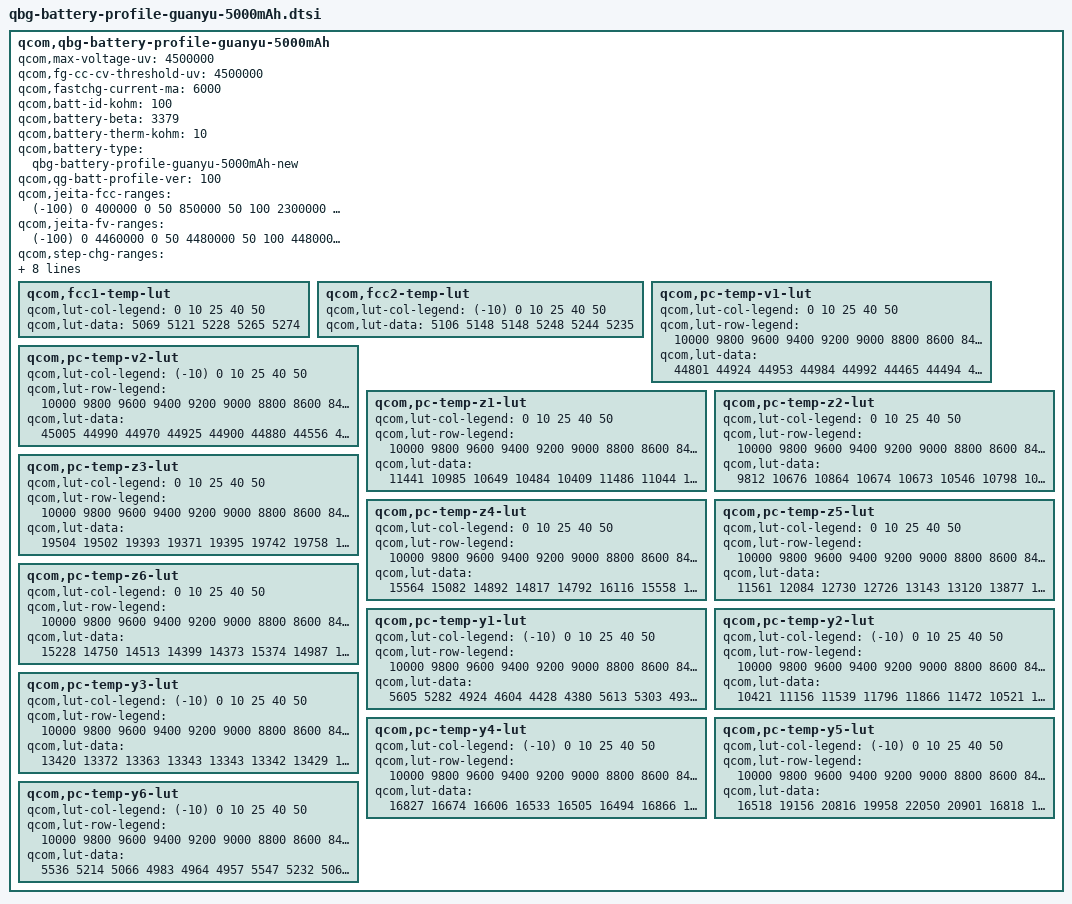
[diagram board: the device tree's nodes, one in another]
qcom,qbg-battery-profile-guanyu-5000mAh {
	qcom,max-voltage-uv = <4500000>;
	qcom,fg-cc-cv-threshold-uv = <4500000>;
	qcom,fastchg-current-ma = <6000>;
	qcom,batt-id-kohm = <100>;
	qcom,battery-beta = <3379>;
	qcom,battery-therm-kohm = <10>;
	qcom,battery-type = "qbg-battery-profile-guanyu-5000mAh-new";
	qcom,qg-batt-profile-ver = <100>;
	qcom,jeita-fcc-ranges = <(-100) 0 400000 0 50 850000 50 100 2300000 100 150 3700000 150 350 6000000 350 480 6000000 480 560 2300000 560 1500 0>;
	qcom,jeita-fv-ranges = <(-100) 0 4460000 0 50 4480000 50 100 4480000 100 150 4480000 150 350 4450000 350 480 4450000 480 560 4100000 560 1500 4100000>;
	qcom,step-chg-ranges = <3600000 4250000 6000000 4250001 4480000 5400000 4480001 4500000 3920000>;
	qcom,vbat-avg-based-step-chg;
	qcom,taper-fcc;
	qcom,jeita-soft-thresholds = <9556 3725>;
	qcom,jeita-hard-thresholds = <17365 2967>;
	qcom,jeita-soft-hys-thresholds = <8799 4060>;
	qcom,jeita-soft-fcc-ua = <5400000 2500000>;
	qcom,jeita-soft-fv-uv = <4480000 4100000>;

	qcom,fcc1-temp-lut {
		qcom,lut-col-legend = <0 10 25 40 50>;
		qcom,lut-data = <5069 5121 5228 5265 5274>;
	};

	qcom,fcc2-temp-lut {
		qcom,lut-col-legend = <(-10) 0 10 25 40 50>;
		qcom,lut-data = <5106 5148 5148 5248 5244 5235>;
	};

	qcom,pc-temp-v1-lut {
		qcom,lut-col-legend = <0 10 25 40 50>;
		qcom,lut-row-legend = <10000 9800 9600 9400 9200 9000 8800 8600 8400 8200 8000 7800 7600 7400 7200 7000 6800 6600 6400 6200 6000 5800 5600 5400 5200 5000 4800 4600 4400 4200 4000 3800 3600 3400 3200 3000 2800 2600 2400 2200 2000 1800 1600 1400 1200 1000 900 800 700 600 500 400 300 200 100 0>;
		qcom,lut-data = <44801 44924 44953 44984 44992
		                44465 44494 44525 44545 44562
		                44212 44226 44228 44219 44227
		                43947 43978 43957 43938 43939
		                43652 43692 43691 43677 43676
		                43363 43400 43403 43393 43396
		                43077 43112 43117 43113 43120
		                42793 42824 42832 42834 42844
		                42505 42546 42565 42575 42586
		                42227 42288 42315 42320 42328
		                41983 42047 42063 42065 42074
		                41745 41812 41820 41816 41824
		                41493 41572 41571 41561 41573
		                41172 41308 41318 41301 41310
		                40762 40996 41056 41045 41045
		                40307 40618 40760 40772 40760
		                39847 40204 40400 40427 40436
		                39442 39795 40007 40038 40047
		                39037 39371 39582 39612 39616
		                38599 38924 39140 39170 39166
		                38126 38423 38640 38692 38694
		                37618 37881 38106 38176 38187
		                37083 37314 37551 37621 37639
		                36544 36755 36990 37044 37052
		                35975 36195 36424 36466 36456
		                35372 35613 35840 35878 35868
		                34739 34996 35225 35262 35254
		                34123 34375 34605 34644 34638
		                33538 33770 33991 34030 34026
		                33042 33271 33458 33481 33482
		                32609 32868 33048 33062 33065
		                32252 32454 32579 32580 32582
		                31911 32110 32182 32182 32182
		                31578 31741 31792 31796 31798
		                31158 31331 31397 31402 31403
		                30626 30853 30971 30976 30978
		                30042 30372 30514 30516 30517
		                29470 29822 29965 29971 29971
		                28938 29277 29418 29425 29426
		                28402 28743 28878 28884 28885
		                27772 28138 28276 28282 28283
		                27050 27492 27633 27639 27640
		                26289 26750 26923 26942 26948
		                25514 26039 26264 26286 26291
		                24678 25358 25644 25665 25669
		                23722 24669 25048 25069 25072
		                22689 24028 24531 24558 24561
		                21698 23455 24076 24113 24115
		                22492 22896 23713 23753 23754
		                22641 22459 23388 23410 23411
		                22692 22402 23115 23095 23095
		                22935 22415 22514 22562 22562
		                22862 22414 22289 22293 22293
		                22036 22236 22245 22277 22277
		                21800 22213 22238 22254 22254
		                18745 19099 19099 19099 19099
		                19111 19111 19111 19111 19111>;
	};

	qcom,pc-temp-v2-lut {
		qcom,lut-col-legend = <(-10) 0 10 25 40 50>;
		qcom,lut-row-legend = <10000 9800 9600 9400 9200 9000 8800 8600 8400 8200 8000 7800 7600 7400 7200 7000 6800 6600 6400 6200 6000 5800 5600 5400 5200 5000 4800 4600 4400 4200 4000 3800 3600 3400 3200 3000 2800 2600 2400 2200 2000 1800 1600 1400 1200 1000 900 800 700 600 500 400 300 200 100 0>;
		qcom,lut-data = <45005 44990 44970 44925 44900 44880
		                44556 44590 44590 44564 44521 44498
		                44197 44272 44291 44294 44216 44183
		                43906 43989 44014 44026 43931 43895
		                43655 43753 43778 43782 43685 43648
		                43442 43549 43573 43556 43466 43431
		                43246 43368 43390 43346 43263 43230
		                43078 43199 43219 43165 43094 43066
		                42931 43041 43057 43002 42936 42910
		                42784 42881 42892 42838 42775 42752
		                42641 42731 42739 42683 42623 42602
		                42496 42582 42587 42527 42473 42454
		                42353 42432 42435 42368 42320 42305
		                42209 42272 42274 42199 42157 42146
		                42066 42106 42108 42022 41984 41977
		                41922 41936 41936 41838 41804 41801
		                41773 41762 41759 41662 41632 41628
		                41595 41559 41544 41436 41403 41398
		                41382 41328 41279 41166 41129 41123
		                41175 41140 41100 40997 40968 40970
		                41016 40997 40968 40877 40858 40869
		                40869 40856 40837 40783 40781 40788
		                40782 40770 40755 40708 40724 40720
		                40715 40703 40692 40634 40676 40659
		                40635 40624 40616 40542 40620 40601
		                40531 40517 40513 40426 40512 40508
		                40466 40462 40462 40316 40371 40383
		                40397 40403 40401 40220 40225 40245
		                40316 40334 40334 40131 40097 40108
		                40206 40238 40242 40014 40004 39984
		                40037 40079 40092 39748 39839 39886
		                39880 39913 39930 39516 39711 39779
		                39765 39768 39767 39379 39567 39608
		                39588 39571 39537 39257 39388 39391
		                39347 39313 39264 39122 39193 39148
		                39087 39056 39006 38946 38958 38874
		                38793 38766 38718 38730 38705 38582
		                38497 38477 38432 38488 38454 38332
		                38260 38243 38202 38229 38199 38134
		                38092 38079 38045 37968 37940 37983
		                38037 38030 37993 37726 37695 37838
		                37949 37959 37936 37490 37452 37659
		                37832 37857 37844 37301 37210 37432
		                37627 37683 37678 37087 36961 37155
		                37344 37430 37428 36842 36739 36870
		                37045 37136 37139 36602 36542 36630
		                36782 36850 36844 36385 36370 36425
		                36558 36604 36585 36184 36204 36229
		                36354 36385 36348 35975 36034 36036
		                36160 36182 36129 35743 35845 35849
		                35973 35997 35940 35459 35601 35664
		                35804 35837 35781 35091 35251 35404
		                35583 35613 35550 34715 34851 35066
		                35289 35313 35243 34349 34430 34649
		                34888 34918 34842 33955 34014 34199
		                34473 34503 34422 33519 33594 33710
		                33980 34007 33924 32965 33023 33127
		                33310 33358 33265 32385 32478 32582
		                32712 32741 32634 31851 31944 32098
		                32231 32240 32155 31056 31165 31312
		                31492 31501 31459 30299 30375 30582
		                30813 30893 30848 29662 29765 30027
		                30258 30261 30191 28946 29168 29412
		                29678 29656 29588 27684 28255 28473
		                28689 28678 28651 26978 27460 27963
		                28197 28202 28145 25704 26798 27040
		                27269 27269 27123 24715 25933 26435
		                26815 26863 26836 23595 25435 25011
		                25875 26055 25936 21852 23826 24452
		                24665 24680 24725 19287 21648 22120
		                22503 22675 22720 16972 19442 19565
		                19794 20086 20287 15010 17588 17772
		                17871 17560 17772 12738 12192 12322
		                12468 11898 11879 12817 12100 12221
		                10423 12028 9322 12632 12051 9243
		                8693 10569 9210 12632 12051 9243>;
	};

	qcom,pc-temp-z1-lut {
		qcom,lut-col-legend = <0 10 25 40 50>;
		qcom,lut-row-legend = <10000 9800 9600 9400 9200 9000 8800 8600 8400 8200 8000 7800 7600 7400 7200 7000 6800 6600 6400 6200 6000 5800 5600 5400 5200 5000 4800 4600 4400 4200 4000 3800 3600 3400 3200 3000 2800 2600 2400 2200 2000 1800 1600 1400 1200 1000 900 800 700 600 500 400 300 200 100 0>;
		qcom,lut-data = <11441 10985 10649 10484 10409
		                11486 11044 10708 10566 10479
		                11487 11042 10711 10568 10480
		                11488 11052 10706 10560 10475
		                11497 11059 10707 10558 10475
		                11516 11063 10707 10558 10475
		                11520 11066 10704 10558 10475
		                11501 11064 10700 10558 10476
		                11469 11056 10695 10557 10476
		                11457 11049 10691 10554 10477
		                11451 11042 10691 10553 10477
		                11446 11037 10691 10553 10477
		                11442 11034 10692 10554 10478
		                11440 11032 10692 10554 10478
		                11450 11032 10692 10555 10481
		                11469 11034 10694 10557 10483
		                11470 11035 10699 10559 10485
		                11458 11033 10704 10562 10487
		                11451 11031 10710 10564 10489
		                11452 11033 10713 10567 10492
		                11456 11042 10713 10570 10495
		                11460 11049 10713 10573 10499
		                11465 11055 10713 10575 10500
		                11467 11059 10716 10576 10500
		                11463 11059 10719 10577 10501
		                11457 11058 10724 10580 10502
		                11461 11058 10728 10585 10505
		                11477 11064 10731 10588 10508
		                11484 11068 10735 10591 10512
		                11479 11068 10738 10594 10515
		                11473 11066 10741 10597 10518
		                11474 11067 10745 10600 10521
		                11479 11075 10753 10605 10523
		                11480 11079 10759 10610 10525
		                11471 11078 10760 10611 10528
		                11462 11076 10759 10611 10531
		                11471 11076 10759 10611 10534
		                11495 11077 10763 10616 10535
		                11503 11079 10769 10621 10536
		                11495 11079 10777 10624 10538
		                11489 11080 10789 10626 10540
		                11497 11085 10792 10629 10542
		                11511 11093 10792 10633 10544
		                11517 11109 10795 10636 10547
		                11517 11115 10800 10638 10549
		                11532 11111 10803 10641 10552
		                11548 11113 10807 10644 10555
		                11524 11103 10805 10646 10555
		                11524 11108 10805 10649 10556
		                11517 11109 10814 10652 10559
		                11516 11112 10814 10655 10563
		                11528 11111 10825 10659 10569
		                11534 11107 10839 10671 10576
		                11534 11116 10857 10684 10587
		                11534 11116 10857 10684 10587>;
	};

	qcom,pc-temp-z2-lut {
		qcom,lut-col-legend = <0 10 25 40 50>;
		qcom,lut-row-legend = <10000 9800 9600 9400 9200 9000 8800 8600 8400 8200 8000 7800 7600 7400 7200 7000 6800 6600 6400 6200 6000 5800 5600 5400 5200 5000 4800 4600 4400 4200 4000 3800 3600 3400 3200 3000 2800 2600 2400 2200 2000 1800 1600 1400 1200 1000 900 800 700 600 500 400 300 200 100 0>;
		qcom,lut-data = <9812 10676 10864 10674 10673
		                10546 10798 10919 11155 10586
		                10629 10868 11055 11232 10742
		                10742 10868 11003 11147 11257
		                10740 10836 10926 11081 11175
		                10641 10771 10832 11031 11093
		                10534 10684 10750 11025 11075
		                10449 10626 10716 11026 11083
		                10388 10578 10768 11037 11075
		                10379 10575 10825 11054 11034
		                10379 10702 10846 11068 11017
		                10379 10839 10862 11087 11037
		                10384 10874 10901 11120 11051
		                10389 10893 11014 11192 11047
		                10393 10929 11100 11244 11041
		                10404 11004 11122 11224 11061
		                10438 11055 11133 11172 11127
		                10482 11101 11179 11188 11201
		                10530 11157 11308 11305 11290
		                10595 11245 11418 11422 11341
		                10667 11361 11466 11466 11347
		                10719 11412 11502 11492 11351
		                10744 11354 11437 11461 11350
		                10747 11277 11214 11295 11351
		                10730 11256 11071 11234 11351
		                10684 11247 11043 11276 11369
		                10644 11246 11029 11351 11414
		                10616 11233 11017 11387 11435
		                10597 11210 11028 11393 11434
		                10590 11200 11053 11395 11431
		                10594 11216 11087 11373 11430
		                10602 11234 11155 11284 11406
		                10606 11239 11188 11224 11367
		                10609 11241 11172 11238 11352
		                10611 11242 11146 11280 11365
		                10615 11235 11135 11331 11400
		                10618 11219 11132 11409 11505
		                10619 11213 11133 11478 11624
		                10621 11214 11146 11507 11633
		                10624 11215 11173 11524 11598
		                10627 11225 11182 11525 11545
		                10629 11236 11163 11462 11386
		                10634 11240 11147 11382 11234
		                10643 11244 11146 11356 11247
		                10664 11249 11147 11350 11264
		                10635 11245 11145 11364 11251
		                10346 11228 11149 11372 11245
		                10281 11268 11168 11376 11253
		                10268 11164 11187 11383 11262
		                10120 11225 11199 11388 11261
		                10106 11186 11196 11405 11291
		                9812 11146 11191 11447 11266
		                9895 11171 11305 11327 11194
		                9769 11179 11256 11205 11093
		                9769 11179 11256 11205 11093>;
	};

	qcom,pc-temp-z3-lut {
		qcom,lut-col-legend = <0 10 25 40 50>;
		qcom,lut-row-legend = <10000 9800 9600 9400 9200 9000 8800 8600 8400 8200 8000 7800 7600 7400 7200 7000 6800 6600 6400 6200 6000 5800 5600 5400 5200 5000 4800 4600 4400 4200 4000 3800 3600 3400 3200 3000 2800 2600 2400 2200 2000 1800 1600 1400 1200 1000 900 800 700 600 500 400 300 200 100 0>;
		qcom,lut-data = <19504 19502 19393 19371 19395
		                19742 19758 19561 19501 19446
		                19848 19864 19651 19545 19485
		                19926 19918 19697 19579 19520
		                19935 19937 19714 19583 19533
		                19938 19942 19717 19582 19536
		                19940 19942 19713 19575 19532
		                19942 19942 19703 19567 19525
		                19944 19943 19693 19564 19522
		                19944 19945 19686 19562 19521
		                19943 19947 19680 19559 19520
		                19940 19946 19679 19557 19518
		                19935 19943 19681 19556 19515
		                19929 19940 19684 19557 19513
		                19922 19936 19688 19559 19515
		                19914 19933 19692 19562 19522
		                19906 19930 19694 19564 19527
		                19897 19924 19696 19565 19529
		                19887 19918 19698 19565 19530
		                19876 19911 19698 19564 19529
		                19865 19903 19695 19560 19525
		                19857 19897 19690 19554 19519
		                19851 19893 19685 19550 19515
		                19844 19889 19680 19549 19513
		                19837 19885 19677 19548 19512
		                19828 19882 19677 19548 19513
		                19820 19879 19678 19551 19522
		                19814 19876 19680 19553 19528
		                19810 19872 19682 19553 19529
		                19805 19869 19684 19552 19529
		                19800 19867 19685 19552 19529
		                19798 19868 19687 19552 19530
		                19797 19871 19693 19553 19531
		                19797 19872 19700 19557 19536
		                19796 19872 19702 19562 19541
		                19795 19869 19702 19564 19542
		                19794 19866 19701 19565 19541
		                19791 19863 19701 19566 19544
		                19795 19864 19703 19569 19551
		                19810 19871 19706 19572 19551
		                19817 19872 19709 19573 19549
		                19818 19861 19707 19570 19546
		                19876 19860 19704 19565 19548
		                19767 19871 19701 19570 19557
		                19419 19415 19667 19566 19543
		                20150 19678 19581 19558 19538
		                20264 20540 19607 19559 19541
		                20277 20352 19700 19561 19542
		                20279 20294 19567 19542 19526
		                20318 20171 19528 19520 19514
		                20324 20230 19523 19518 19514
		                20277 20042 19365 19513 19474
		                20292 20263 19677 19497 19543
		                20189 20105 19589 19482 19547
		                20189 20105 19589 19482 19547>;
	};

	qcom,pc-temp-z4-lut {
		qcom,lut-col-legend = <0 10 25 40 50>;
		qcom,lut-row-legend = <10000 9800 9600 9400 9200 9000 8800 8600 8400 8200 8000 7800 7600 7400 7200 7000 6800 6600 6400 6200 6000 5800 5600 5400 5200 5000 4800 4600 4400 4200 4000 3800 3600 3400 3200 3000 2800 2600 2400 2200 2000 1800 1600 1400 1200 1000 900 800 700 600 500 400 300 200 100 0>;
		qcom,lut-data = <15564 15082 14892 14817 14792
		                16116 15558 14902 14727 14734
		                16046 15618 15054 14805 14704
		                15816 15454 15102 14837 14764
		                15565 15236 15034 14838 14784
		                15332 15098 14966 14839 14790
		                15147 15005 14927 14828 14781
		                14986 14932 14895 14810 14766
		                14858 14877 14872 14794 14755
		                14779 14834 14854 14781 14748
		                14725 14801 14840 14772 14742
		                14675 14776 14825 14765 14738
		                14628 14757 14807 14759 14734
		                14609 14744 14788 14753 14729
		                14605 14734 14774 14748 14725
		                14604 14727 14764 14744 14722
		                14601 14722 14757 14740 14719
		                14596 14719 14753 14737 14716
		                14590 14716 14749 14733 14713
		                14584 14712 14744 14728 14709
		                14578 14704 14736 14724 14707
		                14571 14698 14728 14721 14705
		                14567 14698 14727 14721 14705
		                14566 14699 14735 14725 14707
		                14586 14707 14743 14732 14712
		                14643 14734 14748 14736 14717
		                14666 14746 14751 14738 14721
		                14662 14743 14751 14738 14723
		                14655 14737 14750 14738 14723
		                14644 14733 14748 14736 14723
		                14630 14736 14754 14741 14726
		                14622 14744 14780 14766 14744
		                14621 14745 14797 14786 14761
		                14624 14741 14790 14784 14760
		                14623 14736 14776 14772 14750
		                14616 14732 14772 14772 14758
		                14608 14730 14774 14784 14788
		                14616 14731 14774 14790 14797
		                14634 14740 14772 14793 14794
		                14639 14749 14772 14793 14788
		                14609 14739 14776 14794 14787
		                14574 14721 14771 14789 14778
		                14080 14715 14767 14785 14775
		                14475 14935 14774 14787 14778
		                14226 14895 14772 14785 14773
		                14289 14330 14719 14771 14756
		                13205 13779 14779 14792 14775
		                13167 13690 15073 14809 14797
		                13043 13675 15055 14792 14775
		                13129 13502 14868 14778 14765
		                13129 13880 14868 14777 14761
		                13652 13639 14656 14780 14773
		                14205 14129 14857 14842 14800
		                14147 13804 14691 14835 14807
		                14147 13804 14691 14835 14807>;
	};

	qcom,pc-temp-z5-lut {
		qcom,lut-col-legend = <0 10 25 40 50>;
		qcom,lut-row-legend = <10000 9800 9600 9400 9200 9000 8800 8600 8400 8200 8000 7800 7600 7400 7200 7000 6800 6600 6400 6200 6000 5800 5600 5400 5200 5000 4800 4600 4400 4200 4000 3800 3600 3400 3200 3000 2800 2600 2400 2200 2000 1800 1600 1400 1200 1000 900 800 700 600 500 400 300 200 100 0>;
		qcom,lut-data = <11561 12084 12730 12726 13143
		                13120 13877 14961 16257 16834
		                13909 14640 15047 15524 16316
		                14248 15311 15401 16272 17011
		                14349 15835 15825 16724 17470
		                14425 16256 16293 17066 17656
		                14470 16621 16704 17359 17840
		                14584 16976 17090 17663 18034
		                14763 17426 17501 17979 18215
		                14992 18121 17874 18268 18397
		                15580 18610 18116 18364 18529
		                16052 18835 18360 18383 18606
		                16069 18869 18628 18427 18634
		                16007 18865 18919 18512 18636
		                15953 18865 19108 18738 18677
		                15920 18937 19076 19142 18836
		                15902 19052 18972 19245 19075
		                15848 19142 18990 19273 19292
		                15705 19254 19559 19345 19415
		                15473 19470 20171 19448 19525
		                15275 19794 20305 19337 19607
		                15210 19983 20127 18788 19749
		                15171 20000 20134 18443 19821
		                15145 19996 20698 19101 19542
		                15163 20084 22110 20481 19515
		                15248 20723 22775 21433 20217
		                15226 21173 22436 21313 21102
		                15085 21099 21583 20775 21079
		                14935 20963 21003 20507 20610
		                14889 20996 20640 20400 19944
		                14919 21325 20515 20432 19265
		                14968 21736 20464 20682 18935
		                14973 21993 20508 21072 19002
		                14967 22364 21278 21915 19722
		                15011 22604 21789 22475 20464
		                15098 22599 21834 22436 20634
		                15127 22611 21582 22220 20582
		                15063 22644 21436 22178 20783
		                16243 22569 21525 22247 21560
		                18344 23326 21572 22179 21815
		                19103 23749 21621 21896 20907
		                18446 23824 21587 21611 20357
		                20068 23589 21607 21208 20624
		                18833 23754 21636 21644 22112
		                19573 21868 21183 21257 21825
		                19081 21817 20972 20884 22261
		                24330 30080 21545 21680 23221
		                24292 26539 24204 22217 23834
		                24033 26174 21367 20542 21140
		                24002 25993 21290 20081 20538
		                23876 26891 21099 19811 20355
		                22863 24418 19881 20182 20134
		                22598 26429 22886 20949 22667
		                20636 25671 22737 21973 23247
		                20636 25671 22737 21973 23247>;
	};

	qcom,pc-temp-z6-lut {
		qcom,lut-col-legend = <0 10 25 40 50>;
		qcom,lut-row-legend = <10000 9800 9600 9400 9200 9000 8800 8600 8400 8200 8000 7800 7600 7400 7200 7000 6800 6600 6400 6200 6000 5800 5600 5400 5200 5000 4800 4600 4400 4200 4000 3800 3600 3400 3200 3000 2800 2600 2400 2200 2000 1800 1600 1400 1200 1000 900 800 700 600 500 400 300 200 100 0>;
		qcom,lut-data = <15228 14750 14513 14399 14373
		                15374 14987 14501 14351 14309
		                15390 14995 14592 14410 14360
		                15290 14948 14602 14423 14382
		                15141 14855 14580 14420 14386
		                15009 14767 14553 14415 14386
		                14904 14692 14529 14408 14382
		                14824 14631 14508 14398 14375
		                14759 14583 14491 14390 14370
		                14710 14548 14477 14383 14366
		                14673 14517 14466 14377 14363
		                14640 14495 14457 14372 14360
		                14610 14481 14449 14367 14356
		                14594 14472 14441 14362 14353
		                14589 14465 14435 14358 14351
		                14585 14459 14430 14355 14349
		                14582 14454 14426 14352 14347
		                14576 14451 14423 14350 14346
		                14571 14447 14420 14348 14345
		                14566 14443 14416 14346 14342
		                14561 14437 14411 14343 14339
		                14557 14433 14408 14341 14338
		                14553 14432 14407 14341 14337
		                14550 14431 14407 14342 14338
		                14550 14432 14408 14345 14340
		                14558 14436 14410 14347 14344
		                14577 14445 14412 14349 14347
		                14588 14453 14414 14350 14348
		                14586 14453 14415 14350 14348
		                14583 14452 14416 14350 14349
		                14580 14451 14418 14351 14350
		                14579 14454 14424 14355 14353
		                14578 14460 14432 14362 14358
		                14579 14462 14434 14366 14361
		                14581 14463 14434 14368 14362
		                14582 14464 14434 14370 14364
		                14583 14466 14434 14371 14366
		                14584 14468 14436 14373 14370
		                14587 14471 14440 14376 14372
		                14591 14475 14442 14378 14371
		                14600 14479 14446 14379 14370
		                14610 14481 14446 14378 14370
		                14600 14476 14444 14377 14370
		                14538 14476 14443 14378 14372
		                14485 14514 14445 14379 14372
		                14505 14496 14434 14374 14365
		                14453 14372 14456 14382 14375
		                14441 14321 14535 14393 14387
		                14399 14313 14520 14385 14378
		                14395 14260 14449 14376 14371
		                14386 14424 14449 14375 14369
		                14528 14354 14368 14374 14376
		                14676 14429 14455 14393 14385
		                14646 14313 14395 14388 14389
		                14646 14313 14395 14388 14389>;
	};

	qcom,pc-temp-y1-lut {
		qcom,lut-col-legend = <(-10) 0 10 25 40 50>;
		qcom,lut-row-legend = <10000 9800 9600 9400 9200 9000 8800 8600 8400 8200 8000 7800 7600 7400 7200 7000 6800 6600 6400 6200 6000 5800 5600 5400 5200 5000 4800 4600 4400 4200 4000 3800 3600 3400 3200 3000 2800 2600 2400 2200 2000 1800 1600 1400 1200 1000 900 800 700 600 500 400 300 200 100 0>;
		qcom,lut-data = <5605 5282 4924 4604 4428 4380
		                5613 5303 4931 4616 4437 4384
		                5627 5313 4937 4623 4443 4384
		                5636 5318 4942 4627 4446 4383
		                5637 5319 4944 4630 4446 4380
		                5637 5318 4945 4632 4445 4376
		                5634 5316 4947 4634 4444 4373
		                5634 5313 4950 4635 4445 4371
		                5645 5311 4952 4635 4446 4369
		                5663 5309 4955 4635 4448 4368
		                5665 5306 4958 4636 4449 4368
		                5660 5299 4959 4638 4449 4370
		                5655 5294 4960 4642 4449 4372
		                5649 5292 4962 4647 4451 4374
		                5632 5291 4965 4651 4453 4377
		                5615 5292 4970 4655 4454 4379
		                5615 5292 4979 4660 4456 4381
		                5623 5290 4984 4666 4458 4384
		                5628 5288 4983 4671 4461 4386
		                5631 5288 4982 4676 4464 4388
		                5633 5289 4981 4682 4467 4390
		                5632 5289 4981 4688 4470 4394
		                5626 5290 4981 4694 4473 4399
		                5621 5291 4980 4698 4477 4404
		                5619 5292 4977 4701 4480 4408
		                5612 5296 4978 4704 4484 4410
		                5606 5302 4982 4708 4487 4412
		                5602 5304 4984 4711 4491 4414
		                5595 5302 4986 4715 4494 4417
		                5590 5299 4987 4717 4497 4419
		                5601 5297 4986 4718 4499 4421
		                5620 5298 4986 4719 4501 4423
		                5621 5299 4987 4721 4504 4425
		                5615 5298 4987 4723 4506 4427
		                5612 5299 4988 4727 4509 4429
		                5612 5302 4988 4730 4511 4431
		                5613 5306 4989 4733 4513 4433
		                5615 5309 4991 4737 4516 4435
		                5618 5307 4992 4740 4518 4437
		                5620 5300 4993 4745 4521 4439
		                5619 5298 4994 4750 4524 4441
		                5607 5299 4994 4752 4526 4443
		                5594 5300 4993 4753 4528 4446
		                5593 5298 4993 4753 4530 4448
		                5600 5296 4994 4757 4531 4450
		                5605 5295 4993 4763 4533 4451
		                5604 5294 4992 4768 4535 4452
		                5603 5293 4992 4771 4537 4453
		                5603 5293 4992 4771 4537 4453>;
	};

	qcom,pc-temp-y2-lut {
		qcom,lut-col-legend = <(-10) 0 10 25 40 50>;
		qcom,lut-row-legend = <10000 9800 9600 9400 9200 9000 8800 8600 8400 8200 8000 7800 7600 7400 7200 7000 6800 6600 6400 6200 6000 5800 5600 5400 5200 5000 4800 4600 4400 4200 4000 3800 3600 3400 3200 3000 2800 2600 2400 2200 2000 1800 1600 1400 1200 1000 900 800 700 600 500 400 300 200 100 0>;
		qcom,lut-data = <10421 11156 11539 11796 11866 11472
		                10521 11190 11522 11700 11752 11642
		                10701 11234 11506 11614 11647 11768
		                10921 11286 11490 11545 11560 11829
		                11091 11335 11472 11497 11497 11849
		                11199 11371 11449 11471 11458 11846
		                11242 11392 11424 11460 11434 11830
		                11276 11402 11400 11455 11416 11805
		                11313 11399 11378 11452 11400 11766
		                11361 11389 11358 11448 11385 11680
		                11404 11366 11343 11442 11371 11556
		                11435 11308 11333 11431 11357 11406
		                11445 11227 11323 11413 11342 11261
		                11375 11137 11310 11389 11326 11152
		                11212 11038 11287 11360 11310 11074
		                11043 10944 11252 11327 11294 11019
		                10864 10861 11206 11288 11277 10980
		                10719 10783 11150 11247 11257 10955
		                10608 10747 11084 11209 11230 10951
		                10536 10738 11014 11171 11199 10976
		                10490 10731 10955 11126 11180 11021
		                10459 10675 10909 11068 11187 11078
		                10435 10587 10873 11025 11212 11133
		                10397 10564 10838 11011 11212 11158
		                10233 10594 10802 11006 11171 11162
		                10002 10631 10763 11005 11141 11167
		                9869 10632 10715 11006 11194 11177
		                9779 10614 10658 11008 11292 11190
		                9739 10607 10608 11009 11330 11202
		                9727 10618 10569 11008 11308 11213
		                9708 10636 10551 11004 11275 11228
		                9686 10641 10562 10996 11256 11252
		                9665 10638 10595 10982 11243 11287
		                9655 10638 10612 10970 11235 11319
		                9649 10640 10605 10959 11226 11355
		                9635 10642 10597 10950 11218 11375
		                9611 10641 10595 10943 11218 11373
		                9598 10637 10595 10939 11227 11358
		                9593 10630 10597 10934 11234 11338
		                9585 10622 10600 10925 11227 11319
		                9545 10611 10604 10915 11211 11303
		                9492 10598 10607 10914 11208 11293
		                9416 10583 10608 10920 11223 11286
		                9342 10559 10610 10928 11236 11284
		                9260 10530 10611 10930 11240 11290
		                9158 10496 10612 10929 11241 11305
		                9049 10460 10609 10928 11240 11315
		                8946 10423 10602 10927 11236 11316
		                8893 10394 10593 10926 11230 11310
		                8893 10394 10593 10926 11230 11310>;
	};

	qcom,pc-temp-y3-lut {
		qcom,lut-col-legend = <(-10) 0 10 25 40 50>;
		qcom,lut-row-legend = <10000 9800 9600 9400 9200 9000 8800 8600 8400 8200 8000 7800 7600 7400 7200 7000 6800 6600 6400 6200 6000 5800 5600 5400 5200 5000 4800 4600 4400 4200 4000 3800 3600 3400 3200 3000 2800 2600 2400 2200 2000 1800 1600 1400 1200 1000 900 800 700 600 500 400 300 200 100 0>;
		qcom,lut-data = <13420 13372 13363 13343 13343 13342
		                13429 13385 13368 13345 13341 13339
		                13438 13398 13374 13347 13339 13336
		                13446 13410 13379 13349 13338 13334
		                13452 13418 13383 13351 13337 13332
		                13454 13422 13385 13352 13336 13332
		                13454 13423 13387 13353 13336 13332
		                13454 13424 13388 13353 13336 13332
		                13453 13424 13389 13353 13336 13333
		                13452 13424 13389 13354 13337 13333
		                13451 13425 13389 13354 13338 13334
		                13447 13426 13390 13354 13338 13334
		                13443 13426 13390 13355 13338 13334
		                13441 13424 13391 13355 13339 13335
		                13440 13422 13393 13355 13340 13336
		                13439 13421 13394 13356 13341 13337
		                13435 13420 13394 13357 13342 13337
		                13429 13419 13394 13359 13343 13338
		                13422 13418 13394 13360 13344 13340
		                13414 13419 13394 13361 13345 13341
		                13407 13419 13394 13362 13346 13342
		                13399 13416 13393 13361 13347 13343
		                13392 13411 13392 13360 13349 13344
		                13385 13408 13391 13358 13348 13343
		                13376 13405 13389 13354 13344 13338
		                13371 13404 13387 13351 13341 13335
		                13372 13402 13386 13349 13340 13334
		                13376 13398 13385 13348 13340 13334
		                13377 13396 13384 13347 13340 13334
		                13375 13395 13384 13346 13339 13333
		                13374 13393 13383 13346 13339 13333
		                13376 13391 13382 13345 13339 13332
		                13382 13390 13382 13345 13339 13332
		                13390 13389 13382 13345 13339 13332
		                13398 13388 13382 13345 13339 13333
		                13407 13387 13382 13346 13339 13333
		                13420 13386 13383 13346 13338 13333
		                13434 13385 13384 13346 13337 13331
		                13450 13385 13385 13346 13337 13330
		                13468 13385 13386 13345 13337 13330
		                13487 13384 13387 13345 13337 13331
		                13506 13383 13388 13345 13338 13333
		                13525 13383 13389 13346 13340 13335
		                13543 13382 13390 13346 13340 13334
		                13562 13382 13391 13345 13338 13332
		                13580 13381 13391 13345 13338 13332
		                13594 13383 13392 13346 13339 13333
		                13594 13383 13392 13346 13339 13333>;
	};

	qcom,pc-temp-y4-lut {
		qcom,lut-col-legend = <(-10) 0 10 25 40 50>;
		qcom,lut-row-legend = <10000 9800 9600 9400 9200 9000 8800 8600 8400 8200 8000 7800 7600 7400 7200 7000 6800 6600 6400 6200 6000 5800 5600 5400 5200 5000 4800 4600 4400 4200 4000 3800 3600 3400 3200 3000 2800 2600 2400 2200 2000 1800 1600 1400 1200 1000 900 800 700 600 500 400 300 200 100 0>;
		qcom,lut-data = <16827 16674 16606 16533 16505 16494
		                16866 16746 16638 16526 16501 16490
		                16916 16825 16670 16522 16499 16488
		                16968 16893 16697 16520 16498 16486
		                16998 16937 16717 16519 16498 16486
		                17009 16952 16728 16521 16499 16486
		                17012 16953 16732 16524 16499 16487
		                17014 16950 16735 16529 16501 16488
		                17015 16940 16740 16535 16503 16489
		                17008 16923 16752 16542 16506 16490
		                16988 16905 16764 16549 16509 16493
		                16964 16888 16772 16558 16514 16496
		                16938 16874 16776 16568 16519 16499
		                16859 16861 16774 16580 16525 16503
		                16673 16848 16766 16593 16533 16508
		                16524 16824 16742 16605 16542 16514
		                16467 16765 16686 16615 16550 16521
		                16425 16704 16639 16625 16559 16528
		                16388 16679 16635 16637 16572 16534
		                16342 16671 16639 16653 16587 16539
		                16312 16669 16644 16656 16591 16544
		                16299 16671 16660 16640 16577 16548
		                16290 16676 16683 16628 16562 16551
		                16278 16679 16689 16625 16555 16544
		                16258 16681 16690 16623 16551 16528
		                16239 16681 16687 16621 16547 16521
		                16223 16675 16672 16614 16539 16518
		                16208 16661 16655 16606 16528 16515
		                16196 16645 16639 16599 16519 16508
		                16185 16629 16624 16592 16511 16499
		                16174 16613 16609 16588 16507 16494
		                16164 16595 16593 16585 16504 16492
		                16159 16582 16578 16582 16500 16490
		                16155 16574 16560 16578 16495 16486
		                16151 16565 16545 16573 16488 16480
		                16146 16552 16537 16569 16482 16476
		                16141 16534 16533 16566 16479 16475
		                16136 16523 16531 16566 16479 16476
		                16127 16525 16533 16568 16482 16480
		                16117 16532 16537 16572 16488 16486
		                16114 16532 16538 16577 16496 16491
		                16113 16519 16536 16582 16506 16495
		                16110 16503 16533 16584 16508 16496
		                16107 16494 16533 16585 16506 16494
		                16104 16491 16533 16585 16505 16493
		                16102 16489 16532 16585 16505 16494
		                16101 16489 16531 16585 16505 16495
		                16101 16489 16531 16585 16505 16495>;
	};

	qcom,pc-temp-y5-lut {
		qcom,lut-col-legend = <(-10) 0 10 25 40 50>;
		qcom,lut-row-legend = <10000 9800 9600 9400 9200 9000 8800 8600 8400 8200 8000 7800 7600 7400 7200 7000 6800 6600 6400 6200 6000 5800 5600 5400 5200 5000 4800 4600 4400 4200 4000 3800 3600 3400 3200 3000 2800 2600 2400 2200 2000 1800 1600 1400 1200 1000 900 800 700 600 500 400 300 200 100 0>;
		qcom,lut-data = <16518 19156 20816 19958 22050 20901
		                16818 19764 21745 21468 22822 21182
		                17174 20430 22379 22318 23272 22321
		                17573 21041 22787 22742 23528 23873
		                18028 21533 22966 22913 23516 25234
		                18497 21745 22957 22780 23280 26101
		                19162 21505 22807 22011 22580 26749
		                19740 21143 22728 21207 21917 28296
		                19790 20907 22848 21019 21805 28614
		                19672 20701 23094 21040 22050 28217
		                19553 20438 22507 20986 21833 27091
		                19327 19757 21192 20567 21017 25510
		                18719 18862 20047 19500 19519 23802
		                18859 18266 19598 17902 17654 21768
		                19682 17668 19055 16421 16626 19967
		                20451 17321 18469 16074 16534 18666
		                21127 17528 17694 16582 17454 17526
		                21407 18222 16268 18436 18633 16576
		                20521 19540 16214 20691 20020 16943
		                18570 22875 18415 24669 22587 19163
		                17426 26193 20987 28251 24320 20842
		                17315 30437 24523 32715 27158 22899
		                17198 33352 28285 36841 29851 25560
		                17191 33453 33082 38462 31521 28594
		                17140 33516 36761 38347 31668 30011
		                17223 33713 37373 37133 31310 30302
		                17338 34035 36433 35396 30921 30014
		                17346 34118 33171 33257 29352 28009
		                17326 34134 30594 30670 27337 25516
		                17360 34138 30591 28444 25519 23535
		                17423 34122 30552 27364 24000 22178
		                17517 34105 30555 27381 23900 22088
		                17682 34105 30661 27559 24411 22652
		                17777 34117 30917 27701 24671 22987
		                17459 34189 31763 27831 24714 23141
		                17094 34232 32819 27985 24771 23245
		                17003 34250 33593 28312 24872 23418
		                16948 34269 34248 28782 25034 23650
		                16903 34192 34775 29184 25243 23894
		                16871 33812 35091 29587 25692 24182
		                16849 33520 35239 29980 26147 24423
		                16846 33518 35321 30416 26395 24506
		                16845 33517 35339 30830 26474 24517
		                16845 33517 35339 30830 26474 24517>;
	};

	qcom,pc-temp-y6-lut {
		qcom,lut-col-legend = <(-10) 0 10 25 40 50>;
		qcom,lut-row-legend = <10000 9800 9600 9400 9200 9000 8800 8600 8400 8200 8000 7800 7600 7400 7200 7000 6800 6600 6400 6200 6000 5800 5600 5400 5200 5000 4800 4600 4400 4200 4000 3800 3600 3400 3200 3000 2800 2600 2400 2200 2000 1800 1600 1400 1200 1000 900 800 700 600 500 400 300 200 100 0>;
		qcom,lut-data = <5536 5214 5066 4983 4964 4957
		                5547 5232 5069 4980 4961 4955
		                5564 5255 5073 4975 4958 4953
		                5587 5280 5077 4970 4954 4951
		                5613 5303 5081 4966 4952 4950
		                5636 5320 5085 4964 4951 4950
		                5656 5331 5089 4963 4951 4949
		                5669 5341 5093 4963 4952 4949
		                5668 5349 5098 4964 4954 4950
		                5648 5356 5104 4968 4957 4951
		                5629 5363 5111 4973 4960 4952
		                5645 5368 5122 4980 4963 4954
		                5705 5371 5142 4989 4967 4955
		                5779 5381 5146 4995 4971 4957
		                5855 5422 5132 4993 4975 4960
		                5913 5459 5107 4974 4978 4961
		                5953 5457 5067 4949 4980 4960
		                5966 5416 5031 4927 4982 4959
		                5946 5393 5043 4908 4975 4962
		                5855 5385 5069 4893 4970 4970
		                5786 5381 5071 4881 4980 4982
		                5744 5387 5057 4882 4997 4993
		                5692 5395 5041 4881 4974 4975
		                5573 5395 5032 4875 4911 4925
		                5471 5393 5021 4862 4887 4912
		                5413 5391 5012 4858 4881 4909
		                5387 5371 5004 4856 4871 4907
		                5381 5320 5000 4856 4868 4907
		                5383 5275 5003 4858 4868 4907
		                5379 5268 5001 4866 4872 4908
		                5361 5309 4999 4883 4875 4910
		                5342 5348 5002 4899 4877 4911
		                5338 5368 5010 4909 4875 4910
		                5336 5379 5019 4916 4875 4909
		                5332 5383 5028 4924 4877 4909
		                5328 5386 5036 4933 4882 4911
		                5326 5388 5044 4942 4892 4915
		                5322 5393 5047 4941 4898 4916
		                5300 5411 5048 4928 4889 4907
		                5290 5436 5053 4919 4879 4897
		                5286 5464 5064 4930 4884 4901
		                5272 5488 5088 4962 4900 4914
		                5220 5505 5105 4971 4907 4921
		                5168 5508 5095 4961 4906 4920
		                5098 5473 5066 4938 4899 4916
		                5033 5420 5035 4923 4898 4917
		                5021 5411 5042 4924 4899 4918
		                5021 5411 5042 4924 4899 4918>;
	};
};
